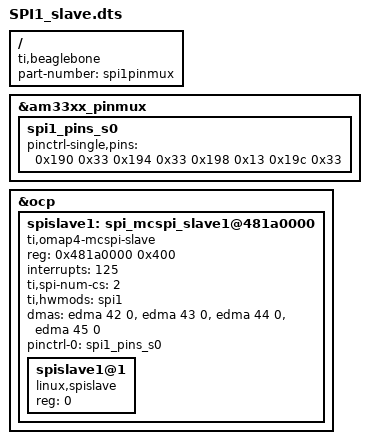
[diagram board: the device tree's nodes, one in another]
/*
 * Copyright (c) 2016 Patryk Mezydlo <pmezydlo - mezydlo.p@gmail.com>
 *
 * This program is free software; you can redistribute it and/or modify it
 * under the terms of the GNU General Public License version 2 as published by
 * the Free Software Foundation.
 */

/dts-v1/;
/plugin/;

/* SPI1 slave dts */
/ {

    compatible = "ti,beaglebone", "ti,beaglebone-black";

    part-number = "spi1pinmux";

    fragment@0 {
        target = <&am33xx_pinmux>;
        __overlay__ {
            spi1_pins_s0: spi1_pins_s0 {
                pinctrl-single,pins = <
                  0x190 0x33  /* spi1_sclk, INPUT_PULLUP  | MODE7 */
                  0x194 0x33  /* spi1_d0,   INPUT_PULLUP  | MODE7 */
                  0x198 0x13  /* spi1_d1,   OUTPUT_PULLUP | MODE7 */
                  0x19c 0x33  /* spi1_cs0,  INPUT_PULLUP  | MODE7 */
                >;
            };
        };
    };

    fragment@1 {
        target = <&ocp>;
        __overlay__ {
            #address-cells = <1>;
            #size-cells = <1>;

	    spislave1: spi_mcspi_slave1@481a0000 {
	        compatible = "ti,omap4-mcspi-slave";
		#address-cells = <1>;
		#size-cells = <0>;
		reg = <0x481a0000 0x400>;
                interrupts = <125>;
		ti,spi-num-cs = <2>;
		ti,hwmods = "spi1";
		dmas = <&edma 42 0
			&edma 43 0
			&edma 44 0
			&edma 45 0>;
		dma-names = "tx0", "rx0", "tx1", "rx1";
		status = "okay";
                pinctrl-names = "default";
                pinctrl-0 = <&spi1_pins_s0>;
                spislave1@1 {
                    reg = <0>;
                    compatible = "linux,spislave";
                };
            };
        };
    };
};
